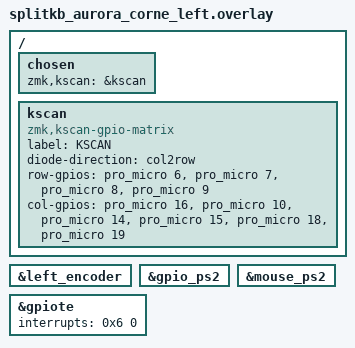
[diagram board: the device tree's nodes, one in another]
/*
 * Copyright (c) 2022 The ZMK Contributors
 *
 * SPDX-License-Identifier: MIT
 */

#include "splitkb_aurora_corne.dtsi"

/ {
    chosen {
        zmk,kscan = &kscan;
    };

    kscan: kscan {
        compatible = "zmk,kscan-gpio-matrix";

        label = "KSCAN";
        diode-direction = "col2row";

        row-gpios
            = <&pro_micro 6 (GPIO_PULL_DOWN | GPIO_ACTIVE_HIGH)>
            , <&pro_micro 7 (GPIO_PULL_DOWN | GPIO_ACTIVE_HIGH)>
            , <&pro_micro 8 (GPIO_PULL_DOWN | GPIO_ACTIVE_HIGH)>
            , <&pro_micro 9 (GPIO_PULL_DOWN | GPIO_ACTIVE_HIGH)>
            ;

        col-gpios
            = <&pro_micro 16 GPIO_ACTIVE_HIGH>
            , <&pro_micro 10 GPIO_ACTIVE_HIGH>
            , <&pro_micro 14 GPIO_ACTIVE_HIGH>
            , <&pro_micro 15 GPIO_ACTIVE_HIGH>
            , <&pro_micro 18 GPIO_ACTIVE_HIGH>
            , <&pro_micro 19 GPIO_ACTIVE_HIGH>
            ;
    };
};

&left_encoder {
    status = "okay";
};

// * TRACKPAD SUPPORT
// Put this in the overlay of the central side (usually left).
// The mouse driver doesn't work on the peripheral.
// If you have your trackpoint on the right side, you need to
// make it the central side first.
//
// Check the Kconfig.defconfig and the `ZMK_SPLIT_ROLE_CENTRAL`
// setting.
&gpio_ps2 {
	status = "okay";
};

&mouse_ps2 {
	status = "okay";
};

// Adjust GPIO interrupt priority to the highest level.
// PS/2 events must be processed within 30-50us. Therefore we change the
// default gpio priority to the highest and we demote all BT interrupt
// priorities by one level.
//
// This allows the PS/2 interrupts to be triggered in time.
&gpiote {
	interrupts = < 0x6 0 >;
};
